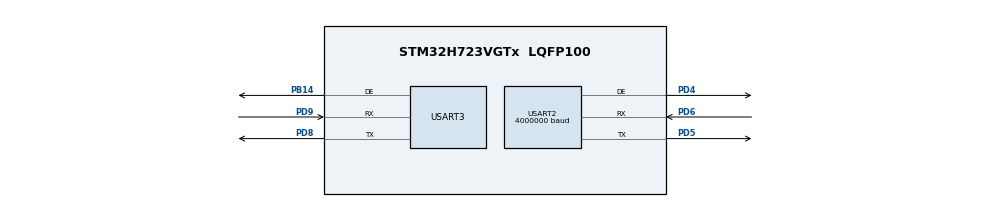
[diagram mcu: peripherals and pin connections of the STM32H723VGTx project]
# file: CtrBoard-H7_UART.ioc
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CORTEX_M7.CPU_DCache=Disabled
CORTEX_M7.CPU_ICache=Disabled
Mcu.Family=STM32H7
Mcu.Name=STM32H723VGTx
Mcu.Package=LQFP100
NVIC.PriorityGroup=NVIC_PRIORITYGROUP_4
PA10.Signal=USART1_RX
PA13(JTMS/SWDIO).Mode=Serial_Wire
PA13(JTMS/SWDIO).Signal=DEBUG_JTMS-SWDIO
PA14(JTCK/SWCLK).Mode=Serial_Wire
PA14(JTCK/SWCLK).Signal=DEBUG_JTCK-SWCLK
PA9.Signal=USART1_TX
PB14.Mode=Hardware Flow Control (RS485)
PB14.Signal=USART3_DE
PD4.Mode=Hardware Flow Control (RS485)
PD4.Signal=USART2_DE
PD5.Mode=Asynchronous
PD5.Signal=USART2_TX
PD6.Mode=Asynchronous
PD6.Signal=USART2_RX
PD8.Mode=Asynchronous
PD8.Signal=USART3_TX
PD9.Mode=Asynchronous
PD9.Signal=USART3_RX
PE2.Signal=USART10_RX
PE3.Signal=USART10_TX
PE7.Signal=UART7_RX
PE8.Signal=UART7_TX
PH0-OSC_IN.Mode=HSE-External-Oscillator
PH0-OSC_IN.Signal=RCC_OSC_IN
PH1-OSC_OUT.Mode=HSE-External-Oscillator
PH1-OSC_OUT.Signal=RCC_OSC_OUT
ProjectManager.HeapSize=0x200
ProjectManager.StackSize=0x400
ProjectManager.TargetToolchain=STM32CubeIDE
RCC.ADCFreq_Value=48375000
RCC.APB1Freq_Value=120000000
RCC.APB2Freq_Value=120000000
RCC.APB3Freq_Value=120000000
RCC.APB4Freq_Value=120000000
RCC.CortexFreq_Value=480000000
RCC.D1PPRE=RCC_APB3_DIV2
RCC.D2PPRE1=RCC_APB1_DIV2
RCC.D2PPRE2=RCC_APB2_DIV2
RCC.D3PPRE=RCC_APB4_DIV2
RCC.DIVM1=2
RCC.DIVN1=40
RCC.DIVP1=1
RCC.DIVQ1=4
RCC.HCLKFreq_Value=240000000
RCC.HPRE=RCC_HCLK_DIV2
RCC.HSE_VALUE=24000000
RCC.PLLFRACN=0
RCC.PLLSourceVirtual=RCC_PLLSOURCE_HSE
RCC.RCC_MCO1Source=RCC_MCO1SOURCE_HSE
RCC.SYSCLKFreq_VALUE=480000000
RCC.SYSCLKSource=RCC_SYSCLKSOURCE_PLLCLK
RCC.USBFreq_Value=120000000
USART2.BaudRate=4000000
USART2.VirtualMode-Asynchronous=VM_ASYNC
USART2.VirtualMode-Hardware\ Flow\ Control\ (RS485)=VM_ASYNC
USART3.VirtualMode-Asynchronous=VM_ASYNC
USART3.VirtualMode-Hardware\ Flow\ Control\ (RS485)=VM_ASYNC
board=custom

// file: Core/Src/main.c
/* USER CODE BEGIN Header */
/**
  ******************************************************************************
  * @file           : main.c
  * @brief          : Main program body
  ******************************************************************************@#�?
  * @attention
  *
  * Copyright (c) 2024 STMicroelectronics.
  * All rights reserved.
  *
  * This software is licensed under terms that can be found in the LICENSE file
  * in the root directory of this software component.
  * If no LICENSE file comes with this software, it is provided AS-IS.
  *
  ******************************************************************************
  */
/* USER CODE END Header */
#include "main.h"
#include "usart.h"
#include "gpio.h"

/* USER CODE BEGIN Includes */
#include "motor_control.h"
#include "unitree_motor.h"
#include "example.h"
/* USER CODE END Includes */

void SystemClock_Config(void);

  int a=0;
int main(void)
{

  /* MCU Configuration--------------------------------------------------------*/

  /* Reset of all peripherals, Initializes the Flash interface and the Systick. */
  HAL_Init();

  /* Configure the system clock */
  SystemClock_Config();

  /* Initialize all configured peripherals */
  MX_GPIO_Init();
  MX_USART2_UART_Init();
  MX_USART3_UART_Init();
  /* USER CODE BEGIN 2 */
    init_example_motor();
  /* USER CODE END 2 */

  /* Infinite loop */
  /* USER CODE BEGIN WHILE */
  while (1)
  {
      a++;
      unitree_motor_control();
      HAL_Delay(100);

    /* USER CODE END WHILE */

  }
}

void SystemClock_Config(void)
{
  RCC_OscInitTypeDef RCC_OscInitStruct = {0};
  RCC_ClkInitTypeDef RCC_ClkInitStruct = {0};

  /** Supply configuration update enable
  */
  HAL_PWREx_ConfigSupply(PWR_LDO_SUPPLY);

  /** Configure the main internal regulator output voltage
  */
  __HAL_PWR_VOLTAGESCALING_CONFIG(PWR_REGULATOR_VOLTAGE_SCALE0);

  while(!__HAL_PWR_GET_FLAG(PWR_FLAG_VOSRDY)) {}

  /** Initializes the RCC Oscillators according to the specified parameters
  * in the RCC_OscInitTypeDef structure.
  */
  RCC_OscInitStruct.OscillatorType = RCC_OSCILLATORTYPE_HSE;
  RCC_OscInitStruct.HSEState = RCC_HSE_ON;
  RCC_OscInitStruct.PLL.PLLState = RCC_PLL_ON;
  RCC_OscInitStruct.PLL.PLLSource = RCC_PLLSOURCE_HSE;
  RCC_OscInitStruct.PLL.PLLM = 2;
  RCC_OscInitStruct.PLL.PLLN = 40;
  RCC_OscInitStruct.PLL.PLLP = 1;
  RCC_OscInitStruct.PLL.PLLQ = 4;
  RCC_OscInitStruct.PLL.PLLR = 2;
  RCC_OscInitStruct.PLL.PLLRGE = RCC_PLL1VCIRANGE_3;
  RCC_OscInitStruct.PLL.PLLVCOSEL = RCC_PLL1VCOWIDE;
  RCC_OscInitStruct.PLL.PLLFRACN = 0;
  if (HAL_RCC_OscConfig(&RCC_OscInitStruct) != HAL_OK)
  {
    Error_Handler();
  }

  /** Initializes the CPU, AHB and APB buses clocks
  */
  RCC_ClkInitStruct.ClockType = RCC_CLOCKTYPE_HCLK|RCC_CLOCKTYPE_SYSCLK
                              |RCC_CLOCKTYPE_PCLK1|RCC_CLOCKTYPE_PCLK2
                              |RCC_CLOCKTYPE_D3PCLK1|RCC_CLOCKTYPE_D1PCLK1;
  RCC_ClkInitStruct.SYSCLKSource = RCC_SYSCLKSOURCE_PLLCLK;
  RCC_ClkInitStruct.SYSCLKDivider = RCC_SYSCLK_DIV1;
  RCC_ClkInitStruct.AHBCLKDivider = RCC_HCLK_DIV2;
  RCC_ClkInitStruct.APB3CLKDivider = RCC_APB3_DIV2;
  RCC_ClkInitStruct.APB1CLKDivider = RCC_APB1_DIV2;
  RCC_ClkInitStruct.APB2CLKDivider = RCC_APB2_DIV2;
  RCC_ClkInitStruct.APB4CLKDivider = RCC_APB4_DIV2;

  if (HAL_RCC_ClockConfig(&RCC_ClkInitStruct, FLASH_LATENCY_3) != HAL_OK)
  {
    Error_Handler();
  }
}

void Error_Handler(void)
{
  __disable_irq();
  while (1)
  {
  }
}
